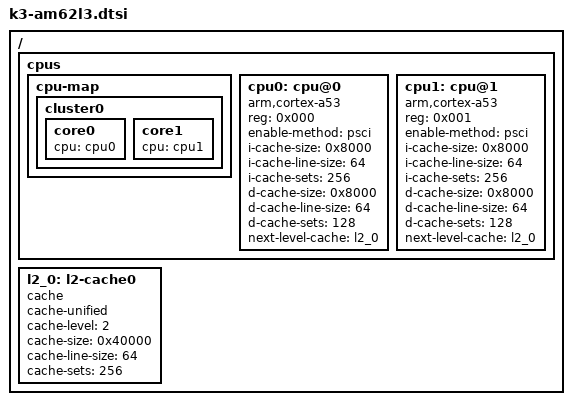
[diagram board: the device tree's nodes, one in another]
// SPDX-License-Identifier: GPL-2.0-only or MIT
/*
 * Device Tree file for the AM62L3 SoC family (Dual Core A53)
 * Copyright (C) 2025 Texas Instruments Incorporated - https://www.ti.com/
 *
 * Technical Reference Manual: https://www.ti.com/lit/pdf/sprujb4
 */

/dts-v1/;

#include "k3-am62l.dtsi"

/ {
	cpus {
		#address-cells = <1>;
		#size-cells = <0>;

		cpu-map {
			cluster0: cluster0 {
				core0 {
					cpu = <&cpu0>;
				};

				core1 {
					cpu = <&cpu1>;
				};
			};
		};

		cpu0: cpu@0 {
			compatible = "arm,cortex-a53";
			reg = <0x000>;
			device_type = "cpu";
			enable-method = "psci";
			i-cache-size = <0x8000>;
			i-cache-line-size = <64>;
			i-cache-sets = <256>;
			d-cache-size = <0x8000>;
			d-cache-line-size = <64>;
			d-cache-sets = <128>;
			next-level-cache = <&l2_0>;
		};

		cpu1: cpu@1 {
			compatible = "arm,cortex-a53";
			reg = <0x001>;
			device_type = "cpu";
			enable-method = "psci";
			i-cache-size = <0x8000>;
			i-cache-line-size = <64>;
			i-cache-sets = <256>;
			d-cache-size = <0x8000>;
			d-cache-line-size = <64>;
			d-cache-sets = <128>;
			next-level-cache = <&l2_0>;
		};
	};

	l2_0: l2-cache0 {
		compatible = "cache";
		cache-unified;
		cache-level = <2>;
		cache-size = <0x40000>;
		cache-line-size = <64>;
		cache-sets = <256>;
	};
};
